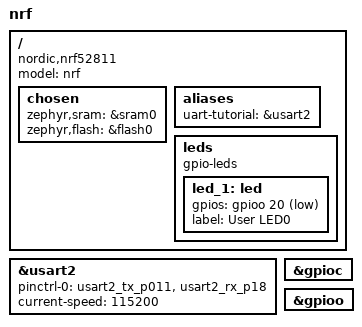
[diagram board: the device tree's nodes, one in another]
/*
 * Copyright (c) 2023 Quasal
 *
 * SPDX-License-Identifier: Apache-2.0
 */

/dts-v1/;
#include <nordic/nrf52811_qfaa.dtsi>
#include <arm/nrf52833dk_nrf52833/nrf52833dk_nrf52833-pinctrl.dtsi>

/ {
    model = "nrf";
    compatible = "nordic,nrf52811";

    chosen {
        zephyr,sram = &sram0;
        zephyr,flash = &flash0;
    };
    aliases {
        uart-tutorial = &usart2;
    };
    leds {
        compatible = "gpio-leds";

        led_1: led {
            gpios = <&gpioo 20 GPIO_ACTIVE_LOW>;
            label = "User LED0";
        };
    };
};



&usart2 {
    pinctrl-0 = <&usart2_tx_p011 &usart2_rx_p18>;
    pinctrl-names = "default";
    current-speed = <115200>;
    status = "okay";
};

&gpioc {
    status = "okay";
};
&gpioo {
    status = "okay";
};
